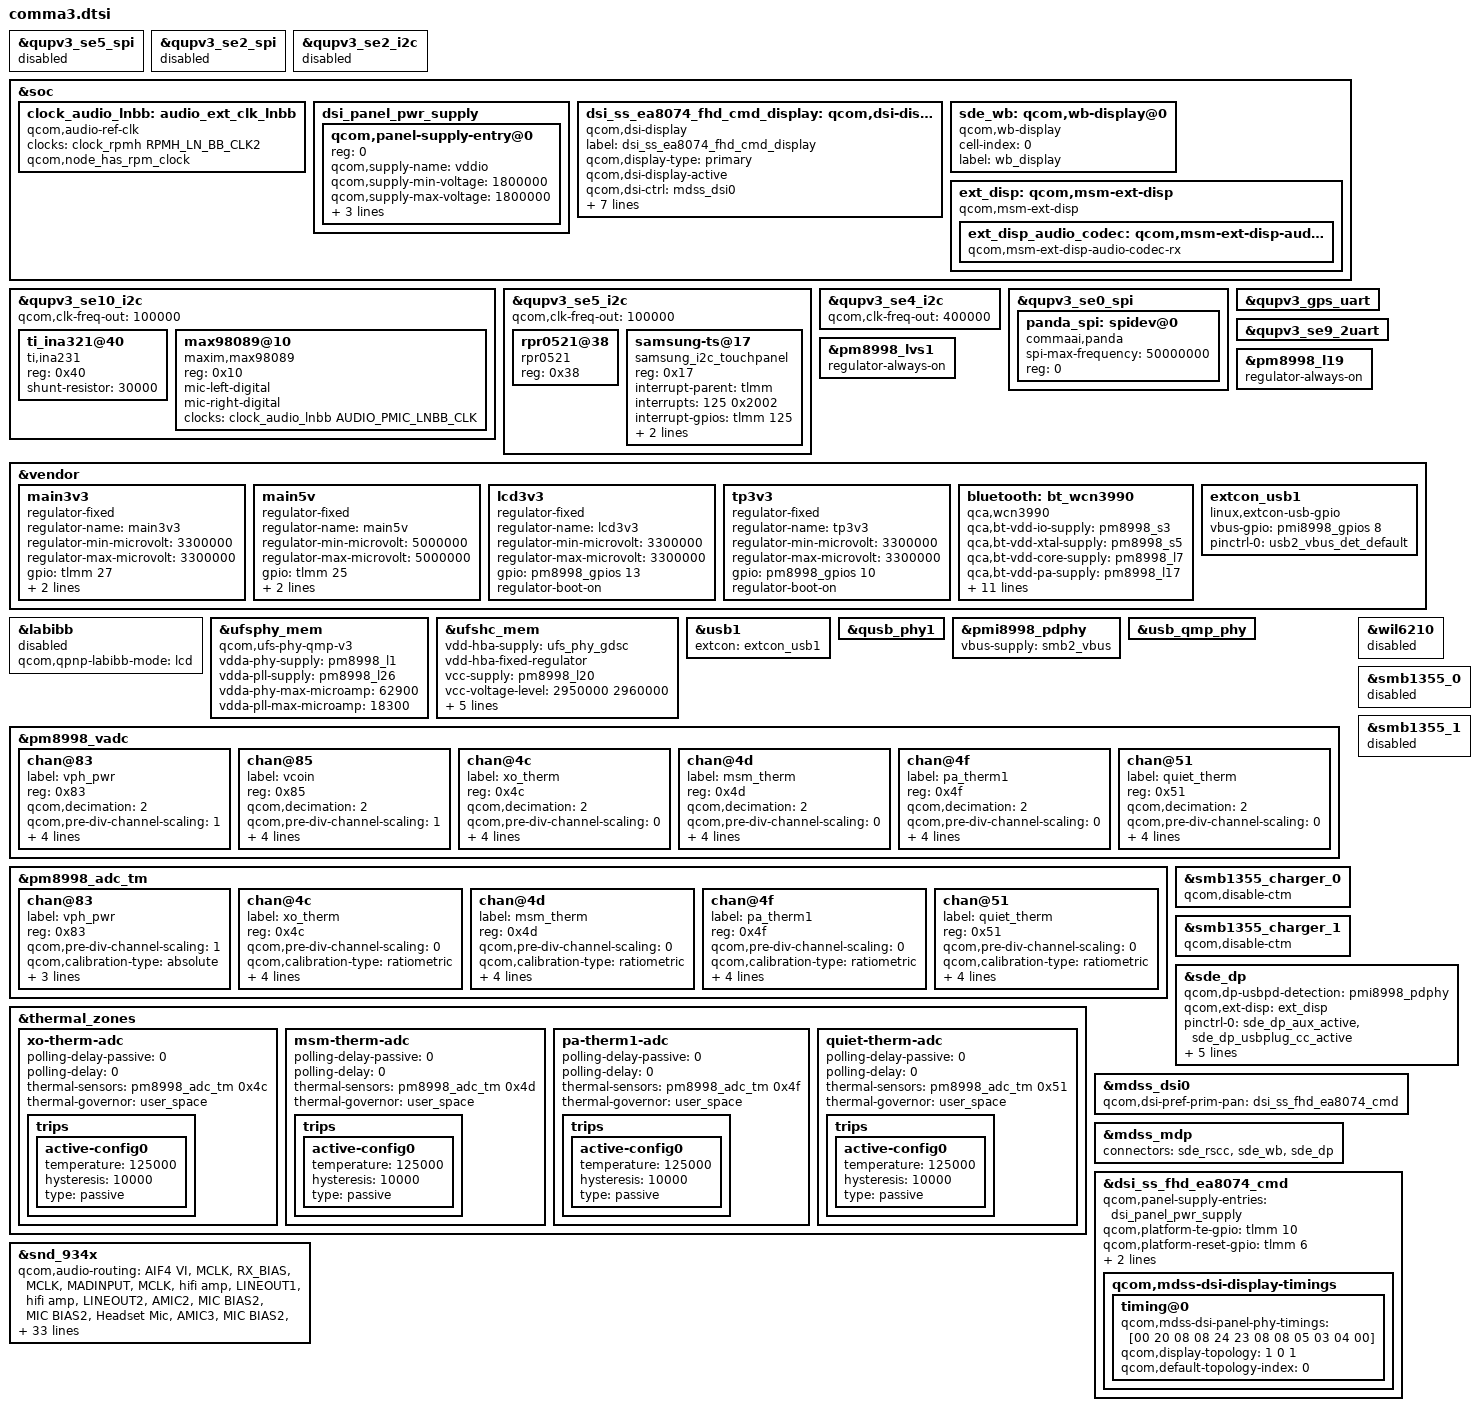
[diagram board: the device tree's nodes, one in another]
#include <dt-bindings/gpio/gpio.h>
#include "sdm845-pmic-overlay.dtsi"
#include "sdm845-pinctrl-overlay.dtsi"
#include "sdm845-camera-sensor-mtp.dtsi"

#include "dsi-panel-ss-fhd-ea8074-cmd.dtsi"
#include <dt-bindings/clock/mdss-10nm-pll-clk.h>
#include <dt-bindings/clock/qcom,audio-ext-clk.h>

/* disable the SPI */
&qupv3_se5_spi {
  status = "disabled";
};

&qupv3_se2_spi {
  status = "disabled";
};

&qupv3_se2_i2c {
  status = "disabled";
};

&soc {
	clock_audio_lnbb: audio_ext_clk_lnbb {
		status = "ok";
		compatible = "qcom,audio-ref-clk";
		clock-names = "osr_clk";
		clocks = <&clock_rpmh RPMH_LN_BB_CLK2>;
		qcom,node_has_rpm_clock;
		#clock-cells = <1>;
	};
};

/* audio and power monitor(ina230) I2C, /dev/i2c-0 */
&qupv3_se10_i2c {
  status = "ok";
  qcom,clk-freq-out = <100000>;

  #include "smb1355.dtsi"

  ti_ina321@40 {
    compatible = "ti,ina231";
    reg = <0x40>;
    /* value is 30mOhm, measured in uohms */
    shunt-resistor = <30000>;
  };

  max98089@10 {
    compatible = "maxim,max98089";
    reg = <0x10>;  /* slave address 0x20 for write, 0x21 for read */
    mic-left-digital;
    mic-right-digital;
		clock-names = "mclk";
		clocks = <&clock_audio_lnbb AUDIO_PMIC_LNBB_CLK>;
  };
};

/* light(RPR-0521RS) and touch panel I2C, /dev/i2c-2 */
&qupv3_se5_i2c {
  status = "ok";
  qcom,clk-freq-out = <100000>;

  rpr0521@38 {
    compatible = "rpr0521";
    reg = <0x38>;
  };

  samsung-ts@17 {
    compatible = "samsung_i2c_touchpanel";
    reg = <0x17>;
    interrupt-parent = <&tlmm>;
		interrupts = <125 0x2002>;
    interrupt-gpios = <&tlmm 125 0x2002>;
    reset-gpios = <&tlmm 104 0>;
    ta-gpios = <&tlmm 128 0>;
  };
};

/* second home of the sensors besides SSC, BLSP4 on tici */
&qupv3_se4_i2c {
  status = "ok";
  qcom,clk-freq-out = <400000>;
};

/* panda SPI */
&qupv3_se0_spi {
  status = "ok";

  panda_spi: spidev@0 {
    status = "ok";
    compatible = "commaai,panda";
    spi-max-frequency = <50000000>;
    reg = <0>;
  };
};

/* GPS UART */
&qupv3_gps_uart {
  status = "ok";
};

/* debug UART */
&qupv3_se9_2uart {
  status = "ok";
};

/* regulators */

// IMU regulators
&pm8998_lvs1 {
  regulator-always-on;
};

&pm8998_l19 {
  regulator-always-on;
};

&vendor {
  main3v3: main3v3 {
    status = "ok";

    compatible = "regulator-fixed";
    regulator-name = "main3v3";
    regulator-min-microvolt = <3300000>;
    regulator-max-microvolt = <3300000>;

    gpio = <&tlmm 27 0>;
    enable-active-high;
    regulator-always-on;
  };

  main5v: main5v {
    status = "ok";

    compatible = "regulator-fixed";
    regulator-name = "main5v";
    regulator-min-microvolt = <5000000>;
    regulator-max-microvolt = <5000000>;

    gpio = <&tlmm 25 0>;
    enable-active-high;
    regulator-always-on;
  };

  lcd3v3: lcd3v3 {
    status = "ok";

    compatible = "regulator-fixed";
    regulator-name = "lcd3v3";
    regulator-min-microvolt = <3300000>;
    regulator-max-microvolt = <3300000>;

    gpio = <&pm8998_gpios 13 0>;
    regulator-boot-on;
  };

  tp3v3: tp3v3 {
   status = "ok";

   compatible = "regulator-fixed";
   regulator-name = "tp3v3";
   regulator-min-microvolt = <3300000>;
   regulator-max-microvolt = <3300000>;

   gpio = <&pm8998_gpios 10 0>;
   regulator-boot-on;
  };
};

/* IMUs are on SSC i2c, have to interact with that firmware */

&vendor {
  bluetooth: bt_wcn3990 {
    compatible = "qca,wcn3990";
    qca,bt-vdd-io-supply = <&pm8998_s3>;
    qca,bt-vdd-xtal-supply = <&pm8998_s5>;
    qca,bt-vdd-core-supply = <&pm8998_l7>;
    qca,bt-vdd-pa-supply = <&pm8998_l17>;
    qca,bt-vdd-ldo-supply = <&pm8998_l25>;

    qca,bt-vdd-io-voltage-level = <1352000 1352000>;
    qca,bt-vdd-xtal-voltage-level = <2040000 2040000>;
    qca,bt-vdd-core-voltage-level = <1800000 1800000>;
    qca,bt-vdd-pa-voltage-level = <1304000 1304000>;
    qca,bt-vdd-ldo-voltage-level = <3312000 3312000>;

    qca,bt-vdd-io-current-level = <1>; /* LPM/PFM */
    qca,bt-vdd-xtal-current-level = <1>; /* LPM/PFM */
    qca,bt-vdd-core-current-level = <1>; /* LPM/PFM */
    qca,bt-vdd-pa-current-level = <1>; /* LPM/PFM */
    qca,bt-vdd-ldo-current-level = <1>; /* LPM/PFM */
  };

  extcon_usb1: extcon_usb1 {
    compatible = "linux,extcon-usb-gpio";
    vbus-gpio = <&pmi8998_gpios 8 GPIO_ACTIVE_HIGH>;

    pinctrl-names = "default";
    pinctrl-0 = <&usb2_vbus_det_default>;
  };
};

&labibb {
  status = "disabled";
  qcom,qpnp-labibb-mode = "lcd";
};

&ufsphy_mem {
  compatible = "qcom,ufs-phy-qmp-v3";

  vdda-phy-supply = <&pm8998_l1>; /* 0.88v */
  vdda-pll-supply = <&pm8998_l26>; /* 1.2v */
  vdda-phy-max-microamp = <62900>;
  vdda-pll-max-microamp = <18300>;

  status = "ok";
};

&ufshc_mem {
  vdd-hba-supply = <&ufs_phy_gdsc>;
  vdd-hba-fixed-regulator;
  vcc-supply = <&pm8998_l20>;
  vcc-voltage-level = <2950000 2960000>;
  vccq2-supply = <&pm8998_s4>;
  vcc-max-microamp = <600000>;
  vccq2-max-microamp = <600000>;

  qcom,vddp-ref-clk-supply = <&pm8998_l2>;
  qcom,vddp-ref-clk-max-microamp = <100>;

  status = "ok";
};

&usb1 {
  status = "okay";
  extcon = <&extcon_usb1>;
};

&qusb_phy1 {
  status = "okay";
};

&pmi8998_pdphy {
  vbus-supply = <&smb2_vbus>;
};

&usb_qmp_phy {
  status = "okay";
};

&pm8998_vadc {
  chan@83 {
    label = "vph_pwr";
    reg = <0x83>;
    qcom,decimation = <2>;
    qcom,pre-div-channel-scaling = <1>;
    qcom,calibration-type = "absolute";
    qcom,scale-function = <0>;
    qcom,hw-settle-time = <0>;
    qcom,fast-avg-setup = <0>;
  };

  chan@85 {
    label = "vcoin";
    reg = <0x85>;
    qcom,decimation = <2>;
    qcom,pre-div-channel-scaling = <1>;
    qcom,calibration-type = "absolute";
    qcom,scale-function = <0>;
    qcom,hw-settle-time = <0>;
    qcom,fast-avg-setup = <0>;
  };

  chan@4c {
    label = "xo_therm";
    reg = <0x4c>;
    qcom,decimation = <2>;
    qcom,pre-div-channel-scaling = <0>;
    qcom,calibration-type = "ratiometric";
    qcom,scale-function = <4>;
    qcom,hw-settle-time = <2>;
    qcom,fast-avg-setup = <0>;
  };

  chan@4d {
    label = "msm_therm";
    reg = <0x4d>;
    qcom,decimation = <2>;
    qcom,pre-div-channel-scaling = <0>;
    qcom,calibration-type = "ratiometric";
    qcom,scale-function = <2>;
    qcom,hw-settle-time = <2>;
    qcom,fast-avg-setup = <0>;
  };

  chan@4f {
    label = "pa_therm1";
    reg = <0x4f>;
    qcom,decimation = <2>;
    qcom,pre-div-channel-scaling = <0>;
    qcom,calibration-type = "ratiometric";
    qcom,scale-function = <2>;
    qcom,hw-settle-time = <2>;
    qcom,fast-avg-setup = <0>;
  };

  chan@51 {
    label = "quiet_therm";
    reg = <0x51>;
    qcom,decimation = <2>;
    qcom,pre-div-channel-scaling = <0>;
    qcom,calibration-type = "ratiometric";
    qcom,scale-function = <2>;
    qcom,hw-settle-time = <2>;
    qcom,fast-avg-setup = <0>;
  };
};

&pm8998_adc_tm {
  chan@83 {
    label = "vph_pwr";
    reg = <0x83>;
    qcom,pre-div-channel-scaling = <1>;
    qcom,calibration-type = "absolute";
    qcom,scale-function = <0>;
    qcom,hw-settle-time = <0>;
    qcom,btm-channel-number = <0x60>;
  };

  chan@4c {
    label = "xo_therm";
    reg = <0x4c>;
    qcom,pre-div-channel-scaling = <0>;
    qcom,calibration-type = "ratiometric";
    qcom,scale-function = <4>;
    qcom,hw-settle-time = <2>;
    qcom,btm-channel-number = <0x68>;
    qcom,thermal-node;
  };

  chan@4d {
    label = "msm_therm";
    reg = <0x4d>;
    qcom,pre-div-channel-scaling = <0>;
    qcom,calibration-type = "ratiometric";
    qcom,scale-function = <2>;
    qcom,hw-settle-time = <2>;
    qcom,btm-channel-number = <0x70>;
    qcom,thermal-node;
  };

  chan@4f {
    label = "pa_therm1";
    reg = <0x4f>;
    qcom,pre-div-channel-scaling = <0>;
    qcom,calibration-type = "ratiometric";
    qcom,scale-function = <2>;
    qcom,hw-settle-time = <2>;
    qcom,btm-channel-number = <0x78>;
    qcom,thermal-node;
  };

  chan@51 {
    label = "quiet_therm";
    reg = <0x51>;
    qcom,pre-div-channel-scaling = <0>;
    qcom,calibration-type = "ratiometric";
    qcom,scale-function = <2>;
    qcom,hw-settle-time = <2>;
    qcom,btm-channel-number = <0x80>;
    qcom,thermal-node;
  };
};

&thermal_zones {
  xo-therm-adc {
    polling-delay-passive = <0>;
    polling-delay = <0>;
    thermal-sensors = <&pm8998_adc_tm 0x4c>;
    thermal-governor = "user_space";

    trips {
      active-config0 {
        temperature = <125000>;
        hysteresis = <10000>;
        type = "passive";
      };
    };
  };

  msm-therm-adc {
    polling-delay-passive = <0>;
    polling-delay = <0>;
    thermal-sensors = <&pm8998_adc_tm 0x4d>;
    thermal-governor = "user_space";

    trips {
      active-config0 {
        temperature = <125000>;
        hysteresis = <10000>;
        type = "passive";
      };
    };
  };

  pa-therm1-adc {
    polling-delay-passive = <0>;
    polling-delay = <0>;
    thermal-sensors = <&pm8998_adc_tm 0x4f>;
    thermal-governor = "user_space";

    trips {
      active-config0 {
        temperature = <125000>;
        hysteresis = <10000>;
        type = "passive";
      };
    };
  };

  quiet-therm-adc {
    polling-delay-passive = <0>;
    polling-delay = <0>;
    thermal-sensors = <&pm8998_adc_tm 0x51>;
    thermal-governor = "user_space";

    trips {
      active-config0 {
        temperature = <125000>;
        hysteresis = <10000>;
        type = "passive";
      };
    };
  };
};

&smb1355_charger_0 {
  status = "ok";
  qcom,disable-ctm;
};

&smb1355_charger_1 {
  status = "ok";
  qcom,disable-ctm;
};

&wil6210 {
  status = "disable";
};

&smb1355_0 {
  status = "disabled";
};

&smb1355_1 {
  status = "disabled";
};

&soc {
	dsi_panel_pwr_supply: dsi_panel_pwr_supply {
		#address-cells = <1>;
		#size-cells = <0>;

		qcom,panel-supply-entry@0 {
			reg = <0>;
			qcom,supply-name = "vddio";
			qcom,supply-min-voltage = <1800000>;
			qcom,supply-max-voltage = <1800000>;
			qcom,supply-enable-load = <62000>;
			qcom,supply-disable-load = <80>;
			qcom,supply-post-on-sleep = <20>;
		};
	};

  dsi_ss_ea8074_fhd_cmd_display: qcom,dsi-display@0 {
    compatible = "qcom,dsi-display";
    label = "dsi_ss_ea8074_fhd_cmd_display";
    qcom,display-type = "primary";
    qcom,dsi-display-active;

    qcom,dsi-ctrl = <&mdss_dsi0>;
    qcom,dsi-phy = <&mdss_dsi_phy0>;
    clocks = <&mdss_dsi0_pll BYTECLK_MUX_0_CLK>, <&mdss_dsi0_pll PCLK_MUX_0_CLK>;
		clock-names = "src_byte_clk", "src_pixel_clk";

    pinctrl-names = "panel_active", "panel_suspend";
    //pinctrl-0 = <&sde_dsi_active &sde_te_active &lcd_3v3_en_n_active &tp_3v3_en_n_active>;
    //pinctrl-1 = <&sde_dsi_suspend &sde_te_suspend &lcd_3v3_en_n_suspend &tp_3v3_en_n_suspend>;
    pinctrl-0 = <&sde_dsi_active &sde_te_active>;
    pinctrl-1 = <&sde_dsi_suspend &sde_te_suspend>;

    qcom,dsi-panel = <&dsi_ss_fhd_ea8074_cmd>;
    vddio-supply = <&pm8998_l14>;

    /*vci-supply = <&disp_vci_vreg>;*/
  };

	sde_wb: qcom,wb-display@0 {
		compatible = "qcom,wb-display";
		cell-index = <0>;
		label = "wb_display";
	};

	ext_disp: qcom,msm-ext-disp {
		compatible = "qcom,msm-ext-disp";

		ext_disp_audio_codec: qcom,msm-ext-disp-audio-codec-rx {
			compatible = "qcom,msm-ext-disp-audio-codec-rx";
		};
	};
};

&sde_dp {
  status = "ok";
	qcom,dp-usbpd-detection = <&pmi8998_pdphy>;
	qcom,ext-disp = <&ext_disp>;

	pinctrl-names = "mdss_dp_active", "mdss_dp_sleep";
	pinctrl-0 = <&sde_dp_aux_active &sde_dp_usbplug_cc_active>;
	pinctrl-1 = <&sde_dp_aux_suspend &sde_dp_usbplug_cc_suspend>;
	qcom,aux-en-gpio = <&tlmm 27 0>;
	qcom,aux-sel-gpio = <&tlmm 51 0>;
	qcom,usbplug-cc-gpio = <&tlmm 38 0>;
};

&mdss_dsi0 {
   qcom,dsi-pref-prim-pan = <&dsi_ss_fhd_ea8074_cmd>;
   status = "ok";
};

&mdss_mdp {
	connectors = <&sde_rscc &sde_wb &sde_dp>;
  //connectors = <&sde_rscc &sde_wb>;
  // crashes without sde_wb
  //connectors = <&sde_rscc>;
};

// Panel
&dsi_ss_fhd_ea8074_cmd {
  qcom,panel-supply-entries = <&dsi_panel_pwr_supply>;

  /* gpios are correct and connected */
  qcom,platform-te-gpio = <&tlmm 10 0>;
  qcom,platform-reset-gpio = <&tlmm 6 0>;
  //qcom,panel-errfg-gpio = <&tlmm 135 0>

  qcom,mdss-dsi-t-clk-post = <0x0e>;
	qcom,mdss-dsi-t-clk-pre = <0x31>;
	qcom,mdss-dsi-display-timings {
		timing@0{
			qcom,mdss-dsi-panel-phy-timings = [00 20 08 08 24 23 08 08 05 03 04 00];
			qcom,display-topology = <1 0 1>;
			qcom,default-topology-index = <0>;
		};
	};
};

&snd_934x {
	qcom,audio-routing =
		"AIF4 VI", "MCLK",
		"RX_BIAS", "MCLK",
		"MADINPUT", "MCLK",
		"hifi amp", "LINEOUT1",
		"hifi amp", "LINEOUT2",
		"AMIC2", "MIC BIAS2",
		"MIC BIAS2", "Headset Mic",
		"AMIC3", "MIC BIAS2",
		"MIC BIAS2", "ANCRight Headset Mic",
		"AMIC4", "MIC BIAS2",
		"MIC BIAS2", "ANCLeft Headset Mic",
		"AMIC5", "MIC BIAS3",
		"MIC BIAS3", "Handset Mic",
		"DMIC0", "MIC BIAS1",
		"MIC BIAS1", "Digital Mic0",
		"DMIC1", "MIC BIAS1",
		"MIC BIAS1", "Digital Mic1",
		"DMIC2", "MIC BIAS3",
		"MIC BIAS3", "Digital Mic2",
		"DMIC3", "MIC BIAS3",
		"MIC BIAS3", "Digital Mic3",
		"DMIC4", "MIC BIAS4",
		"MIC BIAS4", "Digital Mic4",
		"DMIC5", "MIC BIAS4",
		"MIC BIAS4", "Digital Mic5",
		"SpkrLeft IN", "SPK1 OUT",
		"SpkrRight IN", "SPK2 OUT";

	qcom,msm-mbhc-hphl-swh = <1>;
	qcom,msm-mbhc-gnd-swh = <1>;
	qcom,msm-mbhc-hs-mic-max-threshold-mv = <1700>;
	qcom,msm-mbhc-hs-mic-min-threshold-mv = <50>;
	/*qcom,hph-en0-gpio = <&tavil_hph_en0>;
	qcom,hph-en1-gpio = <&tavil_hph_en1>;*/
	qcom,tavil-mclk-clk-freq = <9600000>;

	asoc-codec = <&stub_codec>, <&ext_disp_audio_codec>;
	asoc-codec-names = "msm-stub-codec.1", "msm-ext-disp-audio-codec-rx";

	/*qcom,usbc-analog-en1-gpio = <&wcd_usbc_analog_en1_gpio>;
	qcom,usbc-analog-en2-gpio = <&tlmm 51 0>;*/

	// mclk 79
	// secondary i2s 81,80,83,82
	// tert i2s 76,75,77,78

	pinctrl-names = "aud_active", "aud_sleep",
		"quat-mi2s-sleep", "quat-mi2s-active",
		"quat-tdm-sleep", "quat-tdm-active";
	pinctrl-0 = <&wcd_usbc_analog_en2_active>;
	pinctrl-1 = <&wcd_usbc_analog_en2_idle>;
	//pinctrl-2 = <&quat_mi2s_sleep &quat_mi2s_sd0_sleep &quat_mi2s_sd1_sleep &quat_mi2s_sd2_sleep &quat_mi2s_sd3_sleep>;
	//pinctrl-3 = <&quat_mi2s_active &quat_mi2s_sd0_active &quat_mi2s_sd1_active &quat_mi2s_sd2_active &quat_mi2s_sd3_active>;
	pinctrl-2 = <&sec_mi2s_sleep &sec_mi2s_mclk_sleep &sec_mi2s_sd0_sleep &sec_mi2s_sd1_sleep &tert_mi2s_sleep &tert_mi2s_sd0_sleep &tert_mi2s_sd1_sleep>;
	pinctrl-3 = <&sec_mi2s_active &sec_mi2s_mclk_active &sec_mi2s_sd0_active &sec_mi2s_sd1_active &tert_mi2s_active &tert_mi2s_sd0_active &tert_mi2s_sd1_active>;
	pinctrl-4 = <&quat_tdm_sleep &quat_tdm_din_sleep &quat_tdm_dout_sleep>;
	pinctrl-5 = <&quat_tdm_active &quat_tdm_din_active &quat_tdm_din_active>;

	/*qcom,wsa-max-devs = <2>;
	qcom,wsa-devs = <&wsa881x_0211>, <&wsa881x_0212>, <&wsa881x_0213>, <&wsa881x_0214>;
	qcom,wsa-aux-dev-prefix = "SpkrLeft", "SpkrRight", "SpkrLeft", "SpkrRight";*/
};

